AUTOSAR XML (schema 00050)
package /ComponentTypes
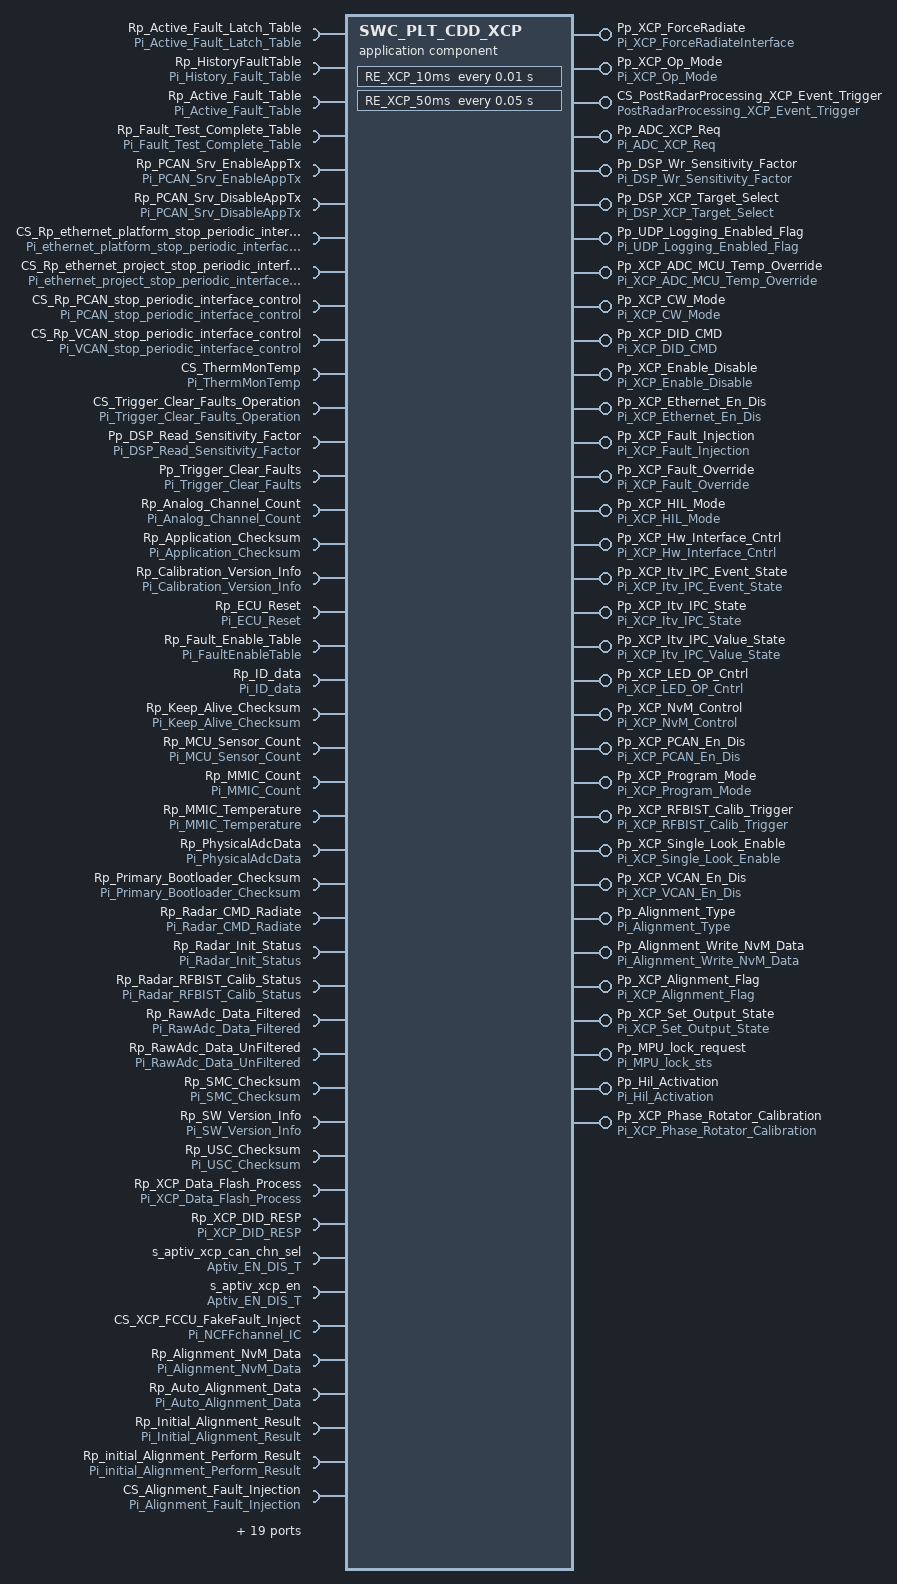
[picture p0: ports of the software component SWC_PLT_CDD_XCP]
  application sw component type SWC_PLT_CDD_XCP
    provide port Pp_XCP_ForceRadiate: nonqueued-sender-com-spec{data-element=De_XCPForceRadiate, init-value=constant-reference=C_Force_Radiate_Init_T}, provided-interface=Pi_XCP_ForceRadiateInterface
    require port Rp_Active_Fault_Latch_Table: nonqueued-receiver-com-spec{data-element=De_ActiveFaultLatchTable, filter=data-filter-type=ALWAYS, init-value=constant-reference=C_Fault_T}, required-interface=Pi_Active_Fault_Latch_Table
    provide port Pp_XCP_Op_Mode: nonqueued-sender-com-spec{data-element=De_XCP_Op_Mode, init-value=0}, provided-interface=Pi_XCP_Op_Mode
    5 x require port:
      Rp_HistoryFaultTable: nonqueued-receiver-com-spec{data-element=De_HistoryFaultTable, filter=data-filter-type=ALWAYS, init-value=constant-reference=C_Fault_T}, required-interface=Pi_History_Fault_Table
      Rp_Active_Fault_Table: nonqueued-receiver-com-spec{data-element=De_ActiveFaultTable, filter=data-filter-type=ALWAYS, init-value=constant-reference=C_Fault_T}, required-interface=Pi_Active_Fault_Table
      Rp_Fault_Test_Complete_Table: nonqueued-receiver-com-spec{data-element=De_FaultTestCompleteTable, filter=data-filter-type=ALWAYS, init-value=constant-reference=C_Fault_T}, required-interface=Pi_Fault_Test_Complete_Table
      Rp_PCAN_Srv_EnableAppTx: client-com-spec=Operation, required-interface=Pi_PCAN_Srv_EnableAppTx
      Rp_PCAN_Srv_DisableAppTx: client-com-spec=Operation, required-interface=Pi_PCAN_Srv_DisableAppTx
    24 x provide port:
      CS_PostRadarProcessing_XCP_Event_Trigger: server-com-spec{operation=Trigger_Look_Based_XCP_Event, queue-length=1}, provided-interface=PostRadarProcessing_XCP_Event_Trigger
      Pp_ADC_XCP_Req: nonqueued-sender-com-spec{data-element=De_ADC_XCP_Req, init-value=0}, provided-interface=Pi_ADC_XCP_Req
      Pp_DSP_Wr_Sensitivity_Factor: nonqueued-sender-com-spec{data-element=De_DSP_Wr_Read_Sensitivity_Factor, init-value=0}, provided-interface=Pi_DSP_Wr_Sensitivity_Factor
      Pp_DSP_XCP_Target_Select: nonqueued-sender-com-spec{data-element=De_DSP_XCP_Target_Select, init-value=fields=[xcp_target_select_cmnd:0, xcp_target_range_idx:12 x 0, xcp_target_doppler_idx:12 x 0]}, provided-interface=Pi_DSP_XCP_Target_Select
      Pp_UDP_Logging_Enabled_Flag: nonqueued-sender-com-spec{data-element=De_UDP_Logging_Enabled_Flag, init-value=1}, provided-interface=Pi_UDP_Logging_Enabled_Flag
      Pp_XCP_ADC_MCU_Temp_Override: nonqueued-sender-com-spec{data-element=De_XCP_ADC_MCU_Temp_Override, init-value=1}, provided-interface=Pi_XCP_ADC_MCU_Temp_Override
      Pp_XCP_CW_Mode: nonqueued-sender-com-spec{data-element=De_XCP_CW_Mode, init-value=85}, provided-interface=Pi_XCP_CW_Mode
      Pp_XCP_DID_CMD: nonqueued-sender-com-spec{data-element=De_XCP_DID_CMD, init-value=fields=[ServiceId:0, Did:0, Data:61 x 0]}, provided-interface=Pi_XCP_DID_CMD
      Pp_XCP_Enable_Disable: server-com-spec{operation=Status, queue-length=1}, provided-interface=Pi_XCP_Enable_Disable
      Pp_XCP_Ethernet_En_Dis: nonqueued-sender-com-spec{data-element=De_XCP_Ethernet_En_Dis, init-value=0}, provided-interface=Pi_XCP_Ethernet_En_Dis
      Pp_XCP_Fault_Injection: nonqueued-sender-com-spec{data-element=De_Xcp_Fault_Injection, init-value=fields=[Sys_Domain:0, Failure_Type:0, Inject_Control:0]}, provided-interface=Pi_XCP_Fault_Injection
      Pp_XCP_Fault_Override: nonqueued-sender-com-spec{data-element=De_XCP_Fault_Override, init-value=constant-reference=C_XCP_Fault_Override}, provided-interface=Pi_XCP_Fault_Override
      Pp_XCP_HIL_Mode: nonqueued-sender-com-spec{data-element=De_XCP_HIL_Mode, init-value=85}, provided-interface=Pi_XCP_HIL_Mode
      Pp_XCP_Hw_Interface_Cntrl: nonqueued-sender-com-spec{data-element=De_Hw_Interface_Cntrl, init-value=fields=[Output_Select_F1_1F_IN:0, Output_State_F1_1F_IN:0]}, provided-interface=Pi_XCP_Hw_Interface_Cntrl
      Pp_XCP_Itv_IPC_Event_State: nonqueued-sender-com-spec{data-element=De_ITV_EVENT, init-value=0}, provided-interface=Pi_XCP_Itv_IPC_Event_State
      Pp_XCP_Itv_IPC_State: nonqueued-sender-com-spec{data-element=De_XCP_SIM_MODE, init-value=0}, provided-interface=Pi_XCP_Itv_IPC_State
      Pp_XCP_Itv_IPC_Value_State: nonqueued-sender-com-spec{data-element=De_ITV_VALUE, init-value=0}, provided-interface=Pi_XCP_Itv_IPC_Value_State
      Pp_XCP_LED_OP_Cntrl: nonqueued-sender-com-spec{data-element=De_XCP_LED_OP_Cntrl, init-value=constant-reference=C_Idt_XCP_LED_Output_Cntrl_T}, provided-interface=Pi_XCP_LED_OP_Cntrl
      Pp_XCP_NvM_Control: nonqueued-sender-com-spec{data-element=De_XCP_NvM_Control, init-value=0}, provided-interface=Pi_XCP_NvM_Control
      Pp_XCP_PCAN_En_Dis: nonqueued-sender-com-spec{data-element=De_XCP_PCAN_En_Dis, init-value=0}, provided-interface=Pi_XCP_PCAN_En_Dis
      Pp_XCP_Program_Mode: nonqueued-sender-com-spec{data-element=De_XCP_Program_Mode, init-value=0}, provided-interface=Pi_XCP_Program_Mode
      Pp_XCP_RFBIST_Calib_Trigger: nonqueued-sender-com-spec{data-element=De_XCP_RFBIST_Calib_Trigger, init-value=85}, provided-interface=Pi_XCP_RFBIST_Calib_Trigger
      Pp_XCP_Single_Look_Enable: nonqueued-sender-com-spec{data-element=De_XCP_Single_Look_Enable, init-value=fields=[single_look_en:0, single_look_select:0]}, provided-interface=Pi_XCP_Single_Look_Enable
      Pp_XCP_VCAN_En_Dis: nonqueued-sender-com-spec{data-element=De_XCP_VCAN_En_Dis, init-value=0}, provided-interface=Pi_XCP_VCAN_En_Dis
    37 x require port:
      CS_Rp_ethernet_platform_stop_periodic_interface_control: client-com-spec=ethernet_platform_stop_periodic_interface_control, required-interface=Pi_ethernet_platform_stop_periodic_interface_control
      CS_Rp_ethernet_project_stop_periodic_interface_control: client-com-spec=Operation, required-interface=Pi_ethernet_project_stop_periodic_interface_control
      CS_Rp_PCAN_stop_periodic_interface_control: client-com-spec=stop_periodic_interface_control, required-interface=Pi_PCAN_stop_periodic_interface_control
      CS_Rp_VCAN_stop_periodic_interface_control: client-com-spec=Operation, required-interface=Pi_VCAN_stop_periodic_interface_control
      CS_ThermMonTemp: client-com-spec=Read, required-interface=Pi_ThermMonTemp
      CS_Trigger_Clear_Faults_Operation: client-com-spec=Operation, required-interface=Pi_Trigger_Clear_Faults_Operation
      Pp_DSP_Read_Sensitivity_Factor: nonqueued-receiver-com-spec{data-element=De_DSP_Read_Sensitivity_Factor, filter=data-filter-type=ALWAYS, init-value=0}, required-interface=Pi_DSP_Read_Sensitivity_Factor
      Pp_Trigger_Clear_Faults: client-com-spec=Operation, required-interface=Pi_Trigger_Clear_Faults
      Rp_Analog_Channel_Count: nonqueued-receiver-com-spec{data-element=De_Analog_Channel_Count, filter=data-filter-type=ALWAYS, init-value=0}, required-interface=Pi_Analog_Channel_Count
      Rp_Application_Checksum: nonqueued-receiver-com-spec{data-element=De_Application_Checksum, filter=data-filter-type=ALWAYS, init-value=0}, required-interface=Pi_Application_Checksum
      Rp_Calibration_Version_Info: nonqueued-receiver-com-spec{data-element=De_Calibration_Version_Info, filter=data-filter-type=ALWAYS, init-value=fields=[SMC_MajorVersion:0, SMC_PlatformRevision:0, SMC_Compatablity:0, USC_MajorVersion:0, USC_PlatformRevision:0, USC_Compatablity:0, Julian_Year:0, Julian_Date:0]}, required-interface=Pi_Calibration_Version_Info
      Rp_ECU_Reset: client-com-spec=ECU_Soft_Reset, required-interface=Pi_ECU_Reset
      Rp_Fault_Enable_Table: nonqueued-receiver-com-spec{data-element=De_FaultEnableTable, filter=data-filter-type=ALWAYS, init-value=constant-reference=C_Fault_T}, required-interface=Pi_FaultEnableTable
      Rp_ID_data: nonqueued-receiver-com-spec{data-element=De_ID_data, filter=data-filter-type=ALWAYS, init-value=constant-reference=C_ID_data}, required-interface=Pi_ID_data
      Rp_Keep_Alive_Checksum: nonqueued-receiver-com-spec{data-element=De_Keep_Alive_Checksum, filter=data-filter-type=ALWAYS, init-value=0}, required-interface=Pi_Keep_Alive_Checksum
      Rp_MCU_Sensor_Count: nonqueued-receiver-com-spec{data-element=De_MCU_Sensor_Count, filter=data-filter-type=ALWAYS, init-value=0}, required-interface=Pi_MCU_Sensor_Count
      Rp_MMIC_Count: nonqueued-receiver-com-spec{data-element=De_MMIC_Count, filter=data-filter-type=ALWAYS, init-value=0}, required-interface=Pi_MMIC_Count
      Rp_MMIC_Temperature: nonqueued-receiver-com-spec{data-element=De_MMIC_Temperature, filter=data-filter-type=ALWAYS, init-value=constant-reference=C_Idt_Type_MMIC_Temperature}, required-interface=Pi_MMIC_Temperature
      Rp_PhysicalAdcData: nonqueued-receiver-com-spec{data-element=De_PhysicalAdcData, filter=data-filter-type=ALWAYS, init-value=fields=[Adc_Board_Rev:0, Adc_Batt_Volt:0, Adc_Pos_Gnd_A:0, Adc_Pos_Gnd_B:0, Adc_Pos_Gnd_C:0, Adc_Pos_Gnd_D:0, Adc_Eth_0v9:0, Adc_Rdi_Detect:0, Adc_MMIC_Temp:0, Adc_Mcu_Temp:0, Validity_Flag:0]}, required-interface=Pi_PhysicalAdcData
      Rp_Primary_Bootloader_Checksum: nonqueued-receiver-com-spec{data-element=De_Primary_Bootloader_Checksum, filter=data-filter-type=ALWAYS, init-value=0}, required-interface=Pi_Primary_Bootloader_Checksum
      Rp_Radar_CMD_Radiate: nonqueued-receiver-com-spec{data-element=De_Radar_CMD_Radiate, filter=data-filter-type=ALWAYS, init-value=0}, required-interface=Pi_Radar_CMD_Radiate
      Rp_Radar_Init_Status: nonqueued-receiver-com-spec{data-element=De_Radar_Init_Status, filter=data-filter-type=ALWAYS, init-value=0}, required-interface=Pi_Radar_Init_Status
      Rp_Radar_RFBIST_Calib_Status: nonqueued-receiver-com-spec{data-element=De_Radar_RFBIST_Calib_Status, filter=data-filter-type=ALWAYS, init-value=fields=[MMIC_1_LNA_Status:0, MMIC_1_MIXER_Status:0, MMIC_2_LNA_Status:0, MMIC_2_MIXER_Status:0]}, required-interface=Pi_Radar_RFBIST_Calib_Status
      Rp_RawAdc_Data_Filtered: nonqueued-receiver-com-spec{data-element=De_RawAdcData, filter=data-filter-type=ALWAYS, init-value=fields=[Adc_Board_Rev:0, Adc_Batt_Volt:0, Adc_Pos_Gnd_A:0, Adc_Pos_Gnd_B:0, Adc_Pos_Gnd_C:0, Adc_Pos_Gnd_D:0, Adc_Eth_0v9:0, Adc_Rdi_Detect:0, Adc_MMIC_Temp:0, Adc_Mcu_Temp:0, Validity_Flag:0, Pos_Validity_Flag:0]}, required-interface=Pi_RawAdc_Data_Filtered
      Rp_RawAdc_Data_UnFiltered: nonqueued-receiver-com-spec{data-element=RawAdcDataUnfiltered, filter=data-filter-type=ALWAYS, init-value=fields=[Adc_Board_Rev:0, Adc_Batt_Volt:0, Adc_Pos_Gnd_A:0, Adc_Pos_Gnd_B:0, Adc_Pos_Gnd_C:0, Adc_Pos_Gnd_D:0, Adc_Eth_0v9:0, Adc_Rdi_Detect:0, Adc_MMIC_Temp:0, Adc_Mcu_Temp:0, Validity_Flag:0]}, required-interface=Pi_RawAdc_Data_UnFiltered
      Rp_SMC_Checksum: nonqueued-receiver-com-spec{data-element=De_SMC_Checksum, filter=data-filter-type=ALWAYS, init-value=0}, required-interface=Pi_SMC_Checksum
      Rp_SW_Version_Info: nonqueued-receiver-com-spec{data-element=De_SW_Version_Info, filter=data-filter-type=ALWAYS, init-value=fields=[SwReleaseRevision:0, SwMajorRevision:0, SwMinorRevision:0, SwFieldRevision:0, DbcMajorRevision:0, DbcMinorRevision:0, FBLMajorRevision:0, FBLMinorRevision:0, FBLPromoteRevision:0, BMMajorRevision:0, BMMinorRevision:0, BMFieldRevision:0, ASRMajorRevision:0, ASRMinorRevision:0, ASRfieldRevision:0]}, required-interface=Pi_SW_Version_Info
      Rp_USC_Checksum: nonqueued-receiver-com-spec{data-element=De_USC_Checksum, filter=data-filter-type=ALWAYS, init-value=0}, required-interface=Pi_USC_Checksum
      Rp_XCP_Data_Flash_Process: nonqueued-receiver-com-spec{data-element=De_Data_Flash_Process, filter=data-filter-type=ALWAYS, init-value=0}, required-interface=Pi_XCP_Data_Flash_Process
      Rp_XCP_DID_RESP: nonqueued-receiver-com-spec{data-element=De_XCP_DID_RESP, filter=data-filter-type=ALWAYS, init-value=fields=[ServiceId:0, Did:0, Data:61 x 0]}, required-interface=Pi_XCP_DID_RESP
      s_aptiv_xcp_can_chn_sel: nonqueued-receiver-com-spec{data-element=EN_DIS, filter=data-filter-type=ALWAYS, init-value=0}, required-interface=Aptiv_EN_DIS_T
      s_aptiv_xcp_en: nonqueued-receiver-com-spec{data-element=EN_DIS, filter=data-filter-type=ALWAYS, init-value=1}, required-interface=Aptiv_EN_DIS_T
      CS_XCP_FCCU_FakeFault_Inject: client-com-spec=Read, required-interface=Pi_NCFFchannel_IC
      Rp_Alignment_NvM_Data: nonqueued-receiver-com-spec{data-element=Alignment_NvM_Data, filter=data-filter-type=ALWAYS, init-value=constant-reference=C_Write_Alignment_NvM_Data}, required-interface=Pi_Alignment_NvM_Data
      Rp_Auto_Alignment_Data: nonqueued-receiver-com-spec{data-element=Auto_Alignment_Data, filter=data-filter-type=ALWAYS, init-value=constant-reference=C_Auto_Alignment_Result}, required-interface=Pi_Auto_Alignment_Data
      Rp_Initial_Alignment_Result: nonqueued-receiver-com-spec{data-element=Initial_Alignment_Result, filter=data-filter-type=ALWAYS, init-value=constant-reference=C_Initial_Alignment_Result}, required-interface=Pi_Initial_Alignment_Result
      Rp_initial_Alignment_Perform_Result: nonqueued-receiver-com-spec{data-element=initial_Alignment_Perform, filter=data-filter-type=ALWAYS, init-value=constant-reference=C_Initial_Alignment_Performance_Result}, required-interface=Pi_initial_Alignment_Perform_Result
    provide port Pp_Alignment_Type: nonqueued-sender-com-spec{data-element=Alignment_Type, init-value=0}, provided-interface=Pi_Alignment_Type
    provide port Pp_Alignment_Write_NvM_Data: nonqueued-sender-com-spec{data-element=Write_Alignment_NvM, init-value=constant-reference=C_Write_Alignment_NvM_Data}, provided-interface=Pi_Alignment_Write_NvM_Data
    provide port Pp_XCP_Alignment_Flag: nonqueued-sender-com-spec{data-element=De_XCP_Alignment_Flag, init-value=85}, provided-interface=Pi_XCP_Alignment_Flag
    15 x require port:
      CS_Alignment_Fault_Injection: client-com-spec=read, required-interface=Pi_Alignment_Fault_Injection
      Rp_Alignment_NvM_Read_Record: nonqueued-receiver-com-spec{data-element=De_Write_Alignment_NvM_Data, filter=data-filter-type=ALWAYS, init-value=constant-reference=C_Write_Alignment_NvM_Data}, required-interface=Pi_Alignment_NvM_Read_Record
      Rp_Customer_SW_Version_Info: nonqueued-receiver-com-spec{data-element=De_Customer_SW_Version_Info, filter=data-filter-type=ALWAYS, init-value=fields=[{short-label=Customer_SW_Version, fields=[Major_Version:0, Minor_Version:0, Patch_Version:0]}, {short-label=Customer_BL_Version, fields=[Major_Version:0, Minor_Version:0, Patch_Version:0]}, {short-label=Customer_BM_Version, fields=[Major_Version:0, Minor_Version:0, Patch_Version:0]}]}, required-interface=Pi_Customer_SW_Version_Info
      Rp_NvM_flag_status: nonqueued-receiver-com-spec{data-element=Pim_write_status, filter=data-filter-type=ALWAYS, init-value=0}, required-interface=Pi_NvM_flag_status
      CS_FailSafe_Fault_Injection: client-com-spec=Read, required-interface=Pi_FailSafe_Fault_Injection
      CS_IPC_Fault_Injection: client-com-spec=Read, required-interface=Pi_IPC_Fault_Injection
      CS_MCU_Safety_Fault_Injection: client-com-spec=Read, required-interface=Pi_MCU_Safety_Fault_Injection
      CS_PlatformTime_Fault_Injection: client-com-spec=Read, required-interface=Pi_PlatformTime_Fault_Injection
      CS_Radar_control_Fault_Injection: client-com-spec=Read, required-interface=Pi_Radar_control_Fault_Injection
      CS_FCCU_Fault_Injection: client-com-spec=Read, required-interface=Pi_FCCU_Fault_Injection
      Rp_BoardRevision_Xcp: nonqueued-receiver-com-spec{data-element=De_BoardRevision_Xcp, filter=data-filter-type=ALWAYS, init-value=0}, required-interface=Pi_BoardRevision_Xcp
      CS_External_Watchdog_Fault_Injection: client-com-spec=Read, required-interface=Pi_External_Watchdog_Fault_Injection
      CS_Modemanager_Fault_Injection: client-com-spec=Read, required-interface=Pi_Modemanager_Fault_Injection
      CS_Diag_Fault_Injection: client-com-spec=Read, required-interface=Pi_Diag_Fault_Injection
      CS_Signal_Integrity_Fault_Injection: client-com-spec=Read, required-interface=Pi_Signal_Integrity_Fault_Injection
    provide port Pp_XCP_Set_Output_State: nonqueued-sender-com-spec{data-element=De_XCP_Set_Output, init-value=constant-reference=C_XCP_Output_State}, provided-interface=Pi_XCP_Set_Output_State
    require port CS_WdgHandler_Fault_Injection: client-com-spec=Read, required-interface=Pi_WdgHandler_Fault_Injection
    require port Rp_MPU_lock_sts: nonqueued-receiver-com-spec{data-element=De_MPU_lock_sts, filter=data-filter-type=ALWAYS, init-value=0}, required-interface=Pi_MPU_lock_sts
    provide port Pp_MPU_lock_request: nonqueued-sender-com-spec{data-element=De_MPU_lock_sts, init-value=0}, provided-interface=Pi_MPU_lock_sts
    provide port Pp_Hil_Activation: nonqueued-sender-com-spec{data-element=De_Hil_Activation, init-value=0}, provided-interface=Pi_Hil_Activation
    require port CS_FCRU_Fault_Injection: client-com-spec=Read, required-interface=Pi_FCRU_Fault_Injection
    provide port Pp_XCP_Phase_Rotator_Calibration: nonqueued-sender-com-spec{data-element=De_XCP_Phase_Rotator_Calibration, init-value=0}, provided-interface=Pi_XCP_Phase_Rotator_Calibration
    require port Rp_VCAN_Srv_DisableAppTx: client-com-spec=Operation, required-interface=Pi_VCAN_Srv_DisableAppTx
    require port Rp_VCAN_Srv_EnableAppTx: client-com-spec=Operation, required-interface=Pi_VCAN_Srv_EnableAppTx
    behavior SWC_PLT_CDD_XCP_InternalBehavior: handle-termination-and-restart=NO-SUPPORT
      timing event TMT_RE_XCP_10ms: start-on-event=RE_XCP_10ms, period=0.01
      timing event SWC_PLT_CDD_XCP_50ms: start-on-event=RE_XCP_50ms, period=0.05
      init event SWC_PLT_CDD_XCP_InitEvent: start-on-event=RE_XCP_Init
      operation invoked event OIT_Pp_XCP_Enable_Disable_Status_Pp_XCP_Enable_Disable_Status: start-on-event=CS_Pp_XCP_Enable_Disable_Status, operation=Pp_XCP_Enable_Disable.Status
      operation invoked event OIT_CS_PostRadarProcessing_XCP_Event_Trigger_Trigger_Look_Based_XCP_Event_CS_PostRadarProcessing_XCP_Event_Trigger_Trigg5AF17252: start-on-event=Trigger_Periodic_XCP_Event, operation=CS_PostRadarProcessing_XCP_Event_Trigger.Trigger_Look_Based_XCP_Event
      5 x runnable:
        RE_XCP_10ms
          data-receive-point-by-arguments:
            5 x access:
              REC_Pp_DSP_Read_Sensitivity_Factor_De_DSP_Read_Sensitivity_Factor: accessed-variable=Pp_DSP_Read_Sensitivity_Factor.De_DSP_Read_Sensitivity_Factor
              REC_Rp_Alignment_NvM_Data_Alignment_NvM_Data: accessed-variable=Rp_Alignment_NvM_Data.Alignment_NvM_Data
              REC_Rp_Auto_Alignment_Data_Auto_Alignment_Data: accessed-variable=Rp_Auto_Alignment_Data.Auto_Alignment_Data
              REC_Rp_Initial_Alignment_Result_Initial_Alignment_Result: accessed-variable=Rp_Initial_Alignment_Result.Initial_Alignment_Result
              REC_Rp_initial_Alignment_Perform_Result_initial_Alignment_Perform: accessed-variable=Rp_initial_Alignment_Perform_Result.initial_Alignment_Perform
          data-send-points:
            7 x access:
              SEND_Pp_ADC_XCP_Req_De_ADC_XCP_Req: accessed-variable=Pp_ADC_XCP_Req.De_ADC_XCP_Req
              SEND_Pp_DSP_Wr_Sensitivity_Factor_De_DSP_Wr_Read_Sensitivity_Factor: accessed-variable=Pp_DSP_Wr_Sensitivity_Factor.De_DSP_Wr_Read_Sensitivity_Factor
              SEND_Pp_DSP_XCP_Target_Select_De_DSP_XCP_Target_Select: accessed-variable=Pp_DSP_XCP_Target_Select.De_DSP_XCP_Target_Select
              SEND_Pp_XCP_Single_Look_Enable_De_XCP_Single_Look_Enable: accessed-variable=Pp_XCP_Single_Look_Enable.De_XCP_Single_Look_Enable
              SEND_Pp_Alignment_Type_Alignment_Type: accessed-variable=Pp_Alignment_Type.Alignment_Type
              SEND_Pp_Alignment_Write_NvM_Data_Write_Alignment_NvM: accessed-variable=Pp_Alignment_Write_NvM_Data.Write_Alignment_NvM
              SEND_Pp_XCP_Alignment_Flag_De_XCP_Alignment_Flag: accessed-variable=Pp_XCP_Alignment_Flag.De_XCP_Alignment_Flag
          5 x sync call:
            SC_CS_Rp_ethernet_platform_stop_periodic_interface_control_ethernet_platform_stop_periodic_interface_control: operation=CS_Rp_ethernet_platform_stop_periodic_interface_control.ethernet_platform_stop_periodic_interface_control
            SC_CS_Rp_ethernet_project_stop_periodic_interface_control_Operation: operation=CS_Rp_ethernet_project_stop_periodic_interface_control.Operation
            SC_CS_Rp_VCAN_stop_periodic_interface_control_Operation: operation=CS_Rp_VCAN_stop_periodic_interface_control.Operation
            SC_Rp_CS_PCAN_stop_periodic_interface_control_stop_periodic_interface_control: operation=CS_Rp_PCAN_stop_periodic_interface_control.stop_periodic_interface_control
            SC_CS_XCP_FCCU_FakeFault_Inject_Read: operation=CS_XCP_FCCU_FakeFault_Inject.Read
        RE_XCP_50ms
          data-receive-point-by-arguments:
            30 x access:
              REC_Rp_Analog_Channel_Count_De_Analog_Channel_Count: accessed-variable=Rp_Analog_Channel_Count.De_Analog_Channel_Count
              REC_Rp_Application_Checksum_De_Application_Checksum: accessed-variable=Rp_Application_Checksum.De_Application_Checksum
              REC_Rp_Calibration_Version_Info_De_Calibration_Version_Info: accessed-variable=Rp_Calibration_Version_Info.De_Calibration_Version_Info
              REC_Rp_Fault_Enable_Table_De_FaultEnableTable: accessed-variable=Rp_Fault_Enable_Table.De_FaultEnableTable
              REC_Rp_Keep_Alive_Checksum_De_Keep_Alive_Checksum: accessed-variable=Rp_Keep_Alive_Checksum.De_Keep_Alive_Checksum
              REC_Rp_MCU_Sensor_Count_De_MCU_Sensor_Count: accessed-variable=Rp_MCU_Sensor_Count.De_MCU_Sensor_Count
              REC_Rp_MMIC_Count_De_MMIC_Count: accessed-variable=Rp_MMIC_Count.De_MMIC_Count
              REC_Rp_MMIC_Temperature_De_MMIC_Temperature: accessed-variable=Rp_MMIC_Temperature.De_MMIC_Temperature
              REC_Rp_PhysicalAdcData_De_PhysicalAdcData: accessed-variable=Rp_PhysicalAdcData.De_PhysicalAdcData
              REC_Rp_Primary_Bootloader_Checksum_De_Primary_Bootloader_Checksum: accessed-variable=Rp_Primary_Bootloader_Checksum.De_Primary_Bootloader_Checksum
              REC_Rp_Radar_CMD_Radiate_De_Radar_CMD_Radiate: accessed-variable=Rp_Radar_CMD_Radiate.De_Radar_CMD_Radiate
              REC_Rp_Radar_Init_Status_De_Radar_Init_Status: accessed-variable=Rp_Radar_Init_Status.De_Radar_Init_Status
              REC_Rp_Radar_RFBIST_Calib_Status_De_Radar_RFBIST_Calib_Status: accessed-variable=Rp_Radar_RFBIST_Calib_Status.De_Radar_RFBIST_Calib_Status
              REC_Rp_RawAdc_Data_Filtered_De_RawAdcData: accessed-variable=Rp_RawAdc_Data_Filtered.De_RawAdcData
              REC_Rp_RawAdc_Data_UnFiltered_RawAdcDataUnfiltered: accessed-variable=Rp_RawAdc_Data_UnFiltered.RawAdcDataUnfiltered
              REC_Rp_SMC_Checksum_De_SMC_Checksum: accessed-variable=Rp_SMC_Checksum.De_SMC_Checksum
              REC_Rp_SW_Version_Info_De_SW_Version_Info: accessed-variable=Rp_SW_Version_Info.De_SW_Version_Info
              REC_Rp_USC_Checksum_De_USC_Checksum: accessed-variable=Rp_USC_Checksum.De_USC_Checksum
              REC_Rp_XCP_Data_Flash_Process_De_Data_Flash_Process: accessed-variable=Rp_XCP_Data_Flash_Process.De_Data_Flash_Process
              REC_Rp_XCP_DID_RESP_De_XCP_DID_RESP: accessed-variable=Rp_XCP_DID_RESP.De_XCP_DID_RESP
              REC_s_aptiv_xcp_can_chn_sel_EN_DIS: accessed-variable=s_aptiv_xcp_can_chn_sel.EN_DIS
              REC_s_aptiv_xcp_en_EN_DIS: accessed-variable=s_aptiv_xcp_en.EN_DIS
              REC_Rp_Read_NvM_record_De_Write_Alignment_NvM_Data: accessed-variable=Rp_Alignment_NvM_Read_Record.De_Write_Alignment_NvM_Data
              REC_Rp_Customer_SW_Version_Info_De_Customer_SW_Version_Info: accessed-variable=Rp_Customer_SW_Version_Info.De_Customer_SW_Version_Info
              REC_Rp_NvM_flag_status_Pim_write_status: accessed-variable=Rp_NvM_flag_status.Pim_write_status
              REC_Rp_MPU_lock_sts_De_MPU_lock_sts: accessed-variable=Rp_MPU_lock_sts.De_MPU_lock_sts
              REC_Rp_Active_Fault_Latch_Table_De_ActiveFaultLatchTable: accessed-variable=Rp_Active_Fault_Latch_Table.De_ActiveFaultLatchTable
              REC_Rp_Active_Fault_Table_De_ActiveFaultTable: accessed-variable=Rp_Active_Fault_Table.De_ActiveFaultTable
              REC_Rp_Fault_Test_Complete_Table_De_FaultTestCompleteTable: accessed-variable=Rp_Fault_Test_Complete_Table.De_FaultTestCompleteTable
              REC_Rp_HistoryFaultTable_De_HistoryFaultTable: accessed-variable=Rp_HistoryFaultTable.De_HistoryFaultTable
          data-send-points:
            25 x access:
              SEND_Pp_XCP_ForceRadiate_De_XCPForceRadiate: accessed-variable=Pp_XCP_ForceRadiate.De_XCPForceRadiate
              SEND_Pp_XCP_Op_Mode_De_XCP_Op_Mode: accessed-variable=Pp_XCP_Op_Mode.De_XCP_Op_Mode
              SEND_Pp_UDP_Logging_Enabled_Flag_De_UDP_Logging_Enabled_Flag: accessed-variable=Pp_UDP_Logging_Enabled_Flag.De_UDP_Logging_Enabled_Flag
              SEND_Pp_XCP_ADC_MCU_Temp_Override_De_XCP_ADC_MCU_Temp_Override: accessed-variable=Pp_XCP_ADC_MCU_Temp_Override.De_XCP_ADC_MCU_Temp_Override
              SEND_Pp_XCP_CW_Mode_De_XCP_CW_Mode: accessed-variable=Pp_XCP_CW_Mode.De_XCP_CW_Mode
              SEND_Pp_XCP_DID_CMD_De_XCP_DID_CMD: accessed-variable=Pp_XCP_DID_CMD.De_XCP_DID_CMD
              SEND_Pp_XCP_Ethernet_En_Dis_De_XCP_Ethernet_En_Dis: accessed-variable=Pp_XCP_Ethernet_En_Dis.De_XCP_Ethernet_En_Dis
              SEND_Pp_XCP_Fault_Injection_De_Xcp_Fault_Injection: accessed-variable=Pp_XCP_Fault_Injection.De_Xcp_Fault_Injection
              SEND_Pp_XCP_Fault_Override_De_XCP_Fault_Override: accessed-variable=Pp_XCP_Fault_Override.De_XCP_Fault_Override
              SEND_Pp_XCP_HIL_Mode_De_XCP_HIL_Mode: accessed-variable=Pp_XCP_HIL_Mode.De_XCP_HIL_Mode
              SEND_Pp_XCP_Hw_Interface_Cntrl_De_Hw_Interface_Cntrl: accessed-variable=Pp_XCP_Hw_Interface_Cntrl.De_Hw_Interface_Cntrl
              SEND_Pp_XCP_Itv_IPC_Event_State_De_ITV_EVENT: accessed-variable=Pp_XCP_Itv_IPC_Event_State.De_ITV_EVENT
              SEND_Pp_XCP_Itv_IPC_State_De_XCP_SIM_MODE: accessed-variable=Pp_XCP_Itv_IPC_State.De_XCP_SIM_MODE
              SEND_Pp_XCP_Itv_IPC_Value_State_De_ITV_VALUE: accessed-variable=Pp_XCP_Itv_IPC_Value_State.De_ITV_VALUE
              SEND_Pp_XCP_LED_OP_Cntrl_De_XCP_LED_OP_Cntrl: accessed-variable=Pp_XCP_LED_OP_Cntrl.De_XCP_LED_OP_Cntrl
              SEND_Pp_XCP_NvM_Control_De_XCP_NvM_Control: accessed-variable=Pp_XCP_NvM_Control.De_XCP_NvM_Control
              SEND_Pp_XCP_PCAN_En_Dis_De_XCP_PCAN_En_Dis: accessed-variable=Pp_XCP_PCAN_En_Dis.De_XCP_PCAN_En_Dis
              SEND_Pp_XCP_Program_Mode_De_XCP_Program_Mode: accessed-variable=Pp_XCP_Program_Mode.De_XCP_Program_Mode
              SEND_Pp_XCP_RFBIST_Calib_Trigger_De_XCP_RFBIST_Calib_Trigger: accessed-variable=Pp_XCP_RFBIST_Calib_Trigger.De_XCP_RFBIST_Calib_Trigger
              SEND_Pp_XCP_Single_Look_Enable_De_XCP_Single_Look_Enable: accessed-variable=Pp_XCP_Single_Look_Enable.De_XCP_Single_Look_Enable
              SEND_Pp_XCP_VCAN_En_Dis_De_XCP_VCAN_En_Dis: accessed-variable=Pp_XCP_VCAN_En_Dis.De_XCP_VCAN_En_Dis
              SEND_Pp_XCP_Set_Output_State_De_XCP_Set_Output: accessed-variable=Pp_XCP_Set_Output_State.De_XCP_Set_Output
              SEND_Pp_MPU_lock_request_De_MPU_lock_sts: accessed-variable=Pp_MPU_lock_request.De_MPU_lock_sts
              SEND_Pp_Hil_Activation_De_Hil_Activation: accessed-variable=Pp_Hil_Activation.De_Hil_Activation
              SEND_Pp_XCP_Phase_Rotator_Calibration_De_XCP_Phase_Rotator_Calibration: accessed-variable=Pp_XCP_Phase_Rotator_Calibration.De_XCP_Phase_Rotator_Calibration
          20 x sync call:
            SC_Rp_PCAN_Srv_DisableAppTx_Operation: operation=Rp_PCAN_Srv_DisableAppTx.Operation
            SC_Rp_PCAN_Srv_EnableAppTx_Operation: operation=Rp_PCAN_Srv_EnableAppTx.Operation
            SC_CS_ECU_Soft_Reset_Operation: operation=Rp_ECU_Reset.ECU_Soft_Reset
            SC_CS_Trigger_Clear_Faults_Operation_Operation: operation=CS_Trigger_Clear_Faults_Operation.Operation
            SC_Pi_ThermMonTemp_Read: operation=CS_ThermMonTemp.Read
            SC_CS_Alignment_Fault_Injection_read: operation=CS_Alignment_Fault_Injection.read
            SC_CS_FCCU_Fault_Injection_Read: operation=CS_FCCU_Fault_Injection.Read
            SC_CS_FailSafe_Fault_Injection_Read: operation=CS_FailSafe_Fault_Injection.Read
            SC_CS_IPC_Fault_Injection_Read: operation=CS_IPC_Fault_Injection.Read
            SC_CS_MCU_Safety_Fault_Injection_Read: operation=CS_MCU_Safety_Fault_Injection.Read
            SC_CS_PlatformTime_Fault_Injection_Read: operation=CS_PlatformTime_Fault_Injection.Read
            SC_CS_Radar_control_Fault_Injection_Read: operation=CS_Radar_control_Fault_Injection.Read
            SC_CS_External_Watchdog_Fault_Injection_Read: operation=CS_External_Watchdog_Fault_Injection.Read
            SC_CS_Modemanager_Fault_Injection_Read: operation=CS_Modemanager_Fault_Injection.Read
            SC_CS_Diag_Fault_Injection_Read: operation=CS_Diag_Fault_Injection.Read
            SC_CS_Signal_Integrity_Fault_Injection_Read: operation=CS_Signal_Integrity_Fault_Injection.Read
            SC_CS_WdgHandler_Fault_Injection_Read: operation=CS_WdgHandler_Fault_Injection.Read
            SC_CS_FCRU_Fault_Injection_Read: operation=CS_FCRU_Fault_Injection.Read
            SC_Rp_VCAN_Srv_DisableAppTx_Operation: operation=Rp_VCAN_Srv_DisableAppTx.Operation
            SC_Rp_VCAN_Srv_EnableAppTx_Operation: operation=Rp_VCAN_Srv_EnableAppTx.Operation
        RE_XCP_Init
          data-receive-point-by-arguments:
            access REC_Rp_ID_data_De_ID_data: accessed-variable=Rp_ID_data.De_ID_data
            access REC_Rp_BoardRevision_Xcp_De_BoardRevision_Xcp: accessed-variable=Rp_BoardRevision_Xcp.De_BoardRevision_Xcp
        CS_Pp_XCP_Enable_Disable_Status
        Trigger_Periodic_XCP_Event
  swc implementation SWC_PLT_CDD_XCP_Implementation: behavior=SWC_PLT_CDD_XCP_InternalBehavior
    code-descriptors:
      code Default: artifact-descriptors=autosar-engineering-object=category=SWSRC
